VERSION ""

NS_ :

BS_:

BU_: BodyControl Klimatisierung System

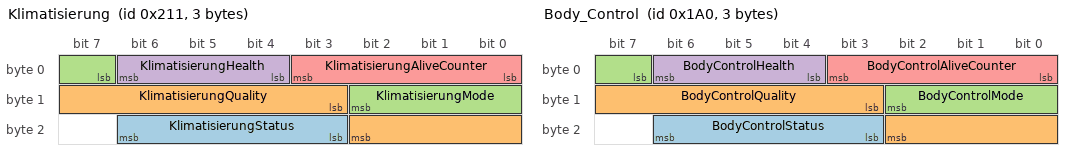
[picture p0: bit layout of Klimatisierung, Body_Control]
BO_ 529 Klimatisierung: 3 Klimatisierung
 SG_ KlimatisierungStatus : 19|4@1+ (1,0) [0.0|15.0] "code"  System
 SG_ KlimatisierungQuality : 11|8@1+ (0.5,0.0) [0.0|100.0] "%"  System
 SG_ KlimatisierungMode : 7|4@1+ (1,0) [0.0|15.0] "code"  System
 SG_ KlimatisierungHealth : 4|3@1+ (1,0) [0.0|7.0] "code"  System
 SG_ KlimatisierungAliveCounter : 0|4@1+ (1,0) [0.0|15.0] "count"  System

BO_ 639 Body_Control_Innenraum_Belegung: 1 BodyControl
 SG_ InnenraumBelegung : 0|4@1+ (1,0) [0.0|9.0] "Personen"  System

BO_ 416 Body_Control: 3 BodyControl
 SG_ BodyControlStatus : 19|4@1+ (1,0) [0.0|15.0] "code"  System
 SG_ BodyControlQuality : 11|8@1+ (0.5,0.0) [0.0|100.0] "%"  System
 SG_ BodyControlMode : 7|4@1+ (1,0) [0.0|15.0] "code"  System
 SG_ BodyControlHealth : 4|3@1+ (1,0) [0.0|7.0] "code"  System
 SG_ BodyControlAliveCounter : 0|4@1+ (1,0) [0.0|15.0] "count"  System

BO_ 644 Klimatisierung_Innenraum_Luftfeu: 2 Klimatisierung
 SG_ InnenraumLuftfeuchte : 0|10@1+ (0.1,0.0) [0.0|100.0] "%"  System

BO_ 643 Klimatisierung_Innenraum_CO2: 2 Klimatisierung
 SG_ InnenraumCO2 : 0|14@1+ (1,0) [0.0|10000.0] "ppm"  System

BO_ 642 Klimatisierung_Innenraum_Tempera: 2 Klimatisierung
 SG_ InnenraumTemperaturSoll : 0|9@1+ (0.1,0.0) [16.0|30.0] "degC"  System

BO_ 645 Klimatisierung_Geblaese_Leistung: 1 Klimatisierung
 SG_ GeblaeseLeistung : 0|7@1+ (1,0) [0.0|100.0] "%"  System

BO_ 640 Body_Control_Innenraum_Bewegungs: 1 BodyControl
 SG_ InnenraumBewegungsintensitaet : 0|7@1+ (1,0) [0.0|100.0] "%"  System

BO_ 641 Klimatisierung_Innenrau_4b169546: 2 Klimatisierung
 SG_ InnenraumTemperaturIst : 0|11@1- (0.1,0.0) [-40.0|85.0] "degC"  System

CM_ BO_ 529 "CanonicalMessage=69aa97e9-8356-4c55-b901-501b50597b48; Network=Karosserie_Komfort_06-S01-CAP-S01; Technology=can_fd";
CM_ SG_ 529 KlimatisierungStatus "CanonicalSignal=736ee8c2-f8b5-4e00-beb0-7b32c12bd33a";
CM_ SG_ 529 KlimatisierungQuality "CanonicalSignal=9273ca70-eab5-4dd1-b1a5-e68057509434";
CM_ SG_ 529 KlimatisierungMode "CanonicalSignal=2e311655-e18e-4c62-8537-b1850ed973ed";
CM_ SG_ 529 KlimatisierungHealth "CanonicalSignal=288b730d-d89d-41c7-9b06-8d84fc385c05";
CM_ SG_ 529 KlimatisierungAliveCounter "CanonicalSignal=30abeb28-d9b9-46de-b522-93bf1a2e87aa";
CM_ BO_ 639 "CanonicalMessage=f2fa6c2d-ce44-4724-9a9a-7e323d8c8632; Network=Karosserie_Komfort_06-S01-CAP-S01; Technology=can_fd";
CM_ SG_ 639 InnenraumBelegung "CanonicalSignal=159a36db-f27a-42e4-9ece-5295411a253c";
CM_ BO_ 416 "CanonicalMessage=a68d2338-444f-4381-8cbc-a6d8067eaac8; Network=Karosserie_Komfort_06-S01-CAP-S01; Technology=can_fd";
CM_ SG_ 416 BodyControlStatus "CanonicalSignal=a332c08a-e325-4a80-a18d-5a9a46fd15b3";
CM_ SG_ 416 BodyControlQuality "CanonicalSignal=7f8a6497-82ba-420b-ac25-0c30c368ca92";
CM_ SG_ 416 BodyControlMode "CanonicalSignal=bad48f83-bfb0-4a11-a2c2-4b1d4f6758fc";
CM_ SG_ 416 BodyControlHealth "CanonicalSignal=d9dbfb7c-41bd-411c-82ea-4b18eb289d13";
CM_ SG_ 416 BodyControlAliveCounter "CanonicalSignal=143557d7-aea9-4cdd-812b-f4e815d0daee";
CM_ BO_ 644 "CanonicalMessage=10839c42-afc5-4011-a160-6df78876e9e9; Network=Karosserie_Komfort_06-S01-CAP-S01; Technology=can_fd";
CM_ SG_ 644 InnenraumLuftfeuchte "CanonicalSignal=01f5b0a5-a7a3-4b0e-89de-15e451cd1773";
CM_ BO_ 643 "CanonicalMessage=0d925314-a589-4e1d-ba46-b384fc5fd7bf; Network=Karosserie_Komfort_06-S01-CAP-S01; Technology=can_fd";
CM_ SG_ 643 InnenraumCO2 "CanonicalSignal=d0ad4b51-818c-43a7-90e1-c8c4d9f621f0";
CM_ BO_ 642 "CanonicalMessage=1fb5db93-53a0-4670-835e-2888db7d20bc; Network=Karosserie_Komfort_06-S01-CAP-S01; Technology=can_fd";
CM_ SG_ 642 InnenraumTemperaturSoll "CanonicalSignal=09b4bb9e-4507-4558-ab2a-40fb1c64a29f";
CM_ BO_ 645 "CanonicalMessage=6c737e81-574e-46bd-aaa7-a04742a3a385; Network=Karosserie_Komfort_06-S01-CAP-S01; Technology=can_fd";
CM_ SG_ 645 GeblaeseLeistung "CanonicalSignal=409e4fea-da05-4545-8c06-955023dc07d2";
CM_ BO_ 640 "CanonicalMessage=7f743fb7-3ec3-4a88-86f1-1bc063813f88; Network=Karosserie_Komfort_06-S01-CAP-S01; Technology=can_fd";
CM_ SG_ 640 InnenraumBewegungsintensitaet "CanonicalSignal=368c979d-8d69-434c-8506-cbbe78c54ecf";
CM_ BO_ 641 "CanonicalMessage=3481249f-cf45-4fac-96d5-13a7dba3e55d; Network=Karosserie_Komfort_06-S01-CAP-S01; Technology=can_fd";
CM_ SG_ 641 InnenraumTemperaturIst "CanonicalSignal=0406efac-496c-4d9d-b4d3-ab104bbff29f";
BA_DEF_ BO_  "VFrameFormat" ENUM  "StandardCAN","ExtendedCAN","StandardCAN_FD","ExtendedCAN_FD";
BA_DEF_DEF_  "VFrameFormat" "0";
BA_ "VFrameFormat" BO_ 529 2;
BA_ "VFrameFormat" BO_ 639 2;
BA_ "VFrameFormat" BO_ 416 2;
BA_ "VFrameFormat" BO_ 644 2;
BA_ "VFrameFormat" BO_ 643 2;
BA_ "VFrameFormat" BO_ 642 2;
BA_ "VFrameFormat" BO_ 645 2;
BA_ "VFrameFormat" BO_ 640 2;
BA_ "VFrameFormat" BO_ 641 2;
